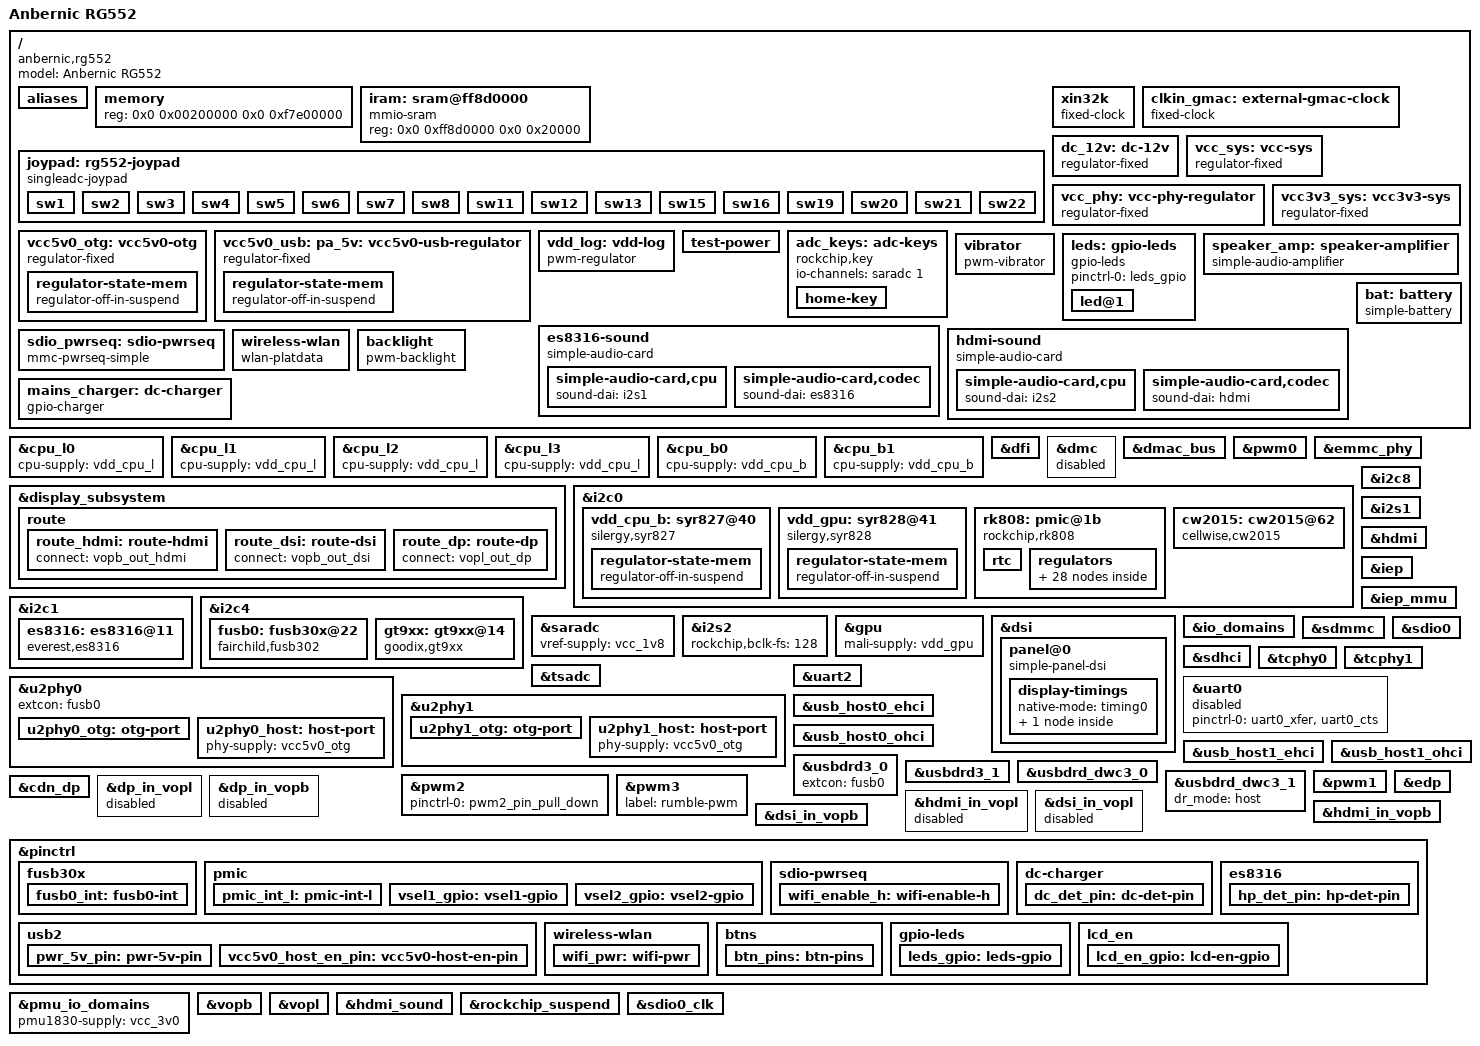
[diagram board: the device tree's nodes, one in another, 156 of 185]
/*
 * Copyright (c) 2017 Fuzhou Rockchip Electronics Co., Ltd
 */

/dts-v1/;
#include <dt-bindings/display/drm_mipi_dsi.h>
#include <dt-bindings/pinctrl/rockchip.h>
#include <dt-bindings/pwm/pwm.h>
#include <dt-bindings/input/input.h>
#include "rk3399.dtsi"
#include "rk3399-android.dtsi"
#include "rk3399-opp.dtsi"
//#include "rk3399-op1-opp.dtsi"
#include "rk3399-vop-clk-set.dtsi"

/ {
	model = "Anbernic RG552";
	compatible = "anbernic,rg552", "rockchip,rk3399";

	aliases {
		mmc0 = &sdio0;
		mmc1 = &sdmmc;
		mmc2 = &sdhci;
	};

	memory {
		device_type = "memory";
		reg = <0x0 0x00200000 0x0 0xf7e00000>;
	};

	
	/* first 64k(0xff8c0000~0xff8d0000) for ddr and suspend */
	iram: sram@ff8d0000 {
		compatible = "mmio-sram";
		reg = <0x0 0xff8d0000 0x0 0x20000>; /* 128k */
	};
	
/*
	gpio_keys: volume-keys {
			compatible = "gpio-keys";
			#address-cells = <1>;
			#size-cells = <0>;
			autorepeat;
			button@0 {
				label = "GPIO BTN-VOLUP";
				linux,code = <KEY_VOLUMEUP>;
				gpios = <&gpio3 RK_PB5 GPIO_ACTIVE_LOW>;
			};
			button@1 {
				label = "GPIO BTN-VOLDN";
				linux,code = <KEY_VOLUMEDOWN>;
				gpios = <&gpio3 RK_PB6 GPIO_ACTIVE_LOW>;
			};
	};
*/
	joypad: rg552-joypad {
		compatible = "singleadc-joypad";
                
		joypad-name = "retrogame_joypad";
		joypad-product = <0x1101>;
		joypad-revision = <0x0100>;
		
		status = "okay";

		/* gpio pincontrol setup */
		pinctrl-names = "default";
		pinctrl-0 = <&btn_pins>;

		/* Analog mux define */
		io-channel-names = "amux_adc";
		io-channels = <&saradc 4>;

		/* adc mux channel count */
		amux-count = <4>;
		/* adc mux select(a,b) gpio */
		amux-a-gpios = <&gpio1 RK_PA1 GPIO_ACTIVE_LOW>;
		amux-b-gpios = <&gpio1 RK_PA0 GPIO_ACTIVE_LOW>;
		/* adc mux enable gpio */
		amux-en-gpios = <&gpio1 RK_PA4 GPIO_ACTIVE_LOW>;

		/* adc calculate scale */
		button-adc-scale = <2>;

		/* adc deadzone range  */
		button-adc-deadzone = <64>;

		/*
		  specifies fuzz value that is used to filter noise from
		  the event stream.
		*/
		button-adc-fuzz = <32>;
		button-adc-flat = <32>;

		/*
		  Analog Stick data tuning value(precent)
		  p = positive direction, n = negative direction
		  report value = (real_adc_data * tuning_value) / 100
		*/
		abs_x-p-tuning = <300>;
		abs_x-n-tuning = <300>;

		abs_y-p-tuning = <300>;
		abs_y-n-tuning = <300>;

		abs_rx-p-tuning = <300>;
		abs_rx-n-tuning = <300>;

		abs_ry-p-tuning = <300>;
		abs_ry-n-tuning = <300>;

		/* poll device interval (ms), adc read interval */
		poll-interval = <10>;

		/* required for RG552(invert) */
		invert-absx;
		invert-absy;

		/* gpio button auto repeat set value : default disable */
		/*
			autorepeat;
		*/

                /*
                               *** RG552 switch layout ***
                |-------------------------------------------------------|
                | sw15(b4) sw21(b6)                   sw20(b7) sw16(b5) |
                |-------------------------------------------------------|
                |        sw19(b12)|-------------------| sw22(b13)       |
                |                 |                   |                 |
                |     sw1(b8)     |                   |     sw8(b2)     |
                |sw3(b10) sw4(b11)|    LCD Display    | sw7(b3) sw5(b1) |
                |     sw2(b9)     |                   |     sw6(b0)     |
                |                 |                   |                 |
                |  sw11(b14)      |-------------------|      sw12(b15)  |
                |                       sw13 (b16)                      |
                |-------------------------------------------------------|
                */

		sw1 {
		        gpios = <&gpio3 RK_PA0 GPIO_ACTIVE_LOW>;
		        label = "GPIO DPAD-UP";
		        linux,code = <103>;
		};
		sw2 {
		        gpios = <&gpio3 RK_PA1 GPIO_ACTIVE_LOW>;
		        label = "GPIO DPAD-DOWN";
		        linux,code = <108>;
		};
		sw3 {
                        gpios = <&gpio3 RK_PA3 GPIO_ACTIVE_LOW>;
		        label = "GPIO DPAD-LEFT";
		        linux,code = <105>;
		};
		sw4 {
                        gpios = <&gpio3 RK_PA2 GPIO_ACTIVE_LOW>;
		        label = "GPIO DPAD-RIGHT";
		        linux,code = <106>;
		};
		sw5 {
		        gpios = <&gpio3 RK_PA6 GPIO_ACTIVE_LOW>;
		        label = "GPIO KEY BTN-A";
		        linux,code = <304>;
		};
		sw6 {
		        gpios = <&gpio3 RK_PA7 GPIO_ACTIVE_LOW>;
		        label = "GPIO BTN-B";
		        linux,code = <305>;
		};
		sw7 {
                        gpios = <&gpio3 RK_PA5 GPIO_ACTIVE_LOW>;
                        label = "GPIO BTN-Y";
                        linux,code = <308>;
                };
                sw8 {
		        gpios = <&gpio3 RK_PA4 GPIO_ACTIVE_LOW>;
		        label = "GPIO BTN-X";
		        linux,code = <307>;
		};
                sw11 {
                        gpios = <&gpio3 RK_PB3 GPIO_ACTIVE_LOW>;
                        label = "GPIO F3";
                        linux,code = <317>;
		};
                sw12 {
                        gpios = <&gpio3 RK_PB4 GPIO_ACTIVE_LOW>;
                        label = "GPIO F4";
                        linux,code = <318>;
		};
                sw13 {
		        gpios = <&gpio3 RK_PC0 GPIO_ACTIVE_LOW>;
                        label = "GPIO F5";
                        linux,code = <127>;
		};
                sw15 {
		        gpios = <&gpio3 RK_PD0 GPIO_ACTIVE_LOW>;
                        label = "GPIO TOP-LEFT";
		        linux,code = <310>;
		};
                sw16 {
		        gpios = <&gpio3 RK_PD2 GPIO_ACTIVE_LOW>;
                        label = "GPIO TOP-RIGHT";
		        linux,code = <311>;
		};
                sw19 {
                        gpios = <&gpio3 RK_PB1 GPIO_ACTIVE_LOW>;
                        label = "GPIO F1";
                        linux,code = <314>;
		};
                sw20 {
		        gpios = <&gpio3 RK_PD3 GPIO_ACTIVE_LOW>;
                        label = "GPIO TOP-RIGHT2";
		        linux,code = <313>;
		};
                sw21 {
                        gpios = <&gpio3 RK_PD1 GPIO_ACTIVE_LOW>;
                        label = "GPIO TOP-LEFT2";
                        linux,code = <312>;
		};
                sw22 {
                        gpios = <&gpio3 RK_PB0 GPIO_ACTIVE_LOW>;
                        label = "GPIO F2";
                        linux,code = <315>;
		};
        };

	xin32k: xin32k {
		compatible = "fixed-clock";
		clock-frequency = <32768>;
		clock-output-names = "xin32k";
		#clock-cells = <0>;
	};

	clkin_gmac: external-gmac-clock {
		compatible = "fixed-clock";
		clock-frequency = <125000000>;
		clock-output-names = "clkin_gmac";
		#clock-cells = <0>;
	};

	dc_12v: dc-12v {
		compatible = "regulator-fixed";
		regulator-name = "dc_12v";
		regulator-always-on;
		regulator-boot-on;
		regulator-min-microvolt = <12000000>;
		regulator-max-microvolt = <12000000>;
	};

	vcc_sys: vcc-sys {
		compatible = "regulator-fixed";
		regulator-name = "vcc_sys";
		regulator-min-microvolt = <5000000>;
		regulator-max-microvolt = <5000000>;
		regulator-always-on;
		vin-supply = <&dc_12v>;
	};

	vcc_phy: vcc-phy-regulator {
		compatible = "regulator-fixed";
		regulator-name = "vcc_phy";
		regulator-always-on;
		regulator-boot-on;
	};

	/* Main 3.3 V supply */
	vcc3v3_sys: vcc3v3-sys {
		compatible = "regulator-fixed";
		regulator-name = "vcc3v3_sys";
		regulator-min-microvolt = <3300000>;
		regulator-max-microvolt = <3300000>;
		regulator-always-on;
		vin-supply = <&vcc_sys>;
	};
	

	/* Regulators supplied by vcc5v0_usb */
	/* USB 3 port power supply regulator  */
	vcc5v0_otg: vcc5v0-otg {
		compatible = "regulator-fixed";
		enable-active-high;
		gpio = <&gpio4 RK_PD2 GPIO_ACTIVE_HIGH>;
		pinctrl-names = "default";
		pinctrl-0 = <&vcc5v0_host_en_pin>;
		regulator-name = "vcc5v0_otg";
		regulator-always-on;
		regulator-min-microvolt = <5000000>;
		regulator-max-microvolt = <5000000>;
		vin-supply = <&vcc5v0_usb>;

		regulator-state-mem {
			regulator-off-in-suspend;
		};
	};
	
	/* 5 V USB power supply */
	vcc5v0_usb: pa_5v: vcc5v0-usb-regulator {
		compatible = "regulator-fixed";
		enable-active-high;
		gpio = <&gpio1 RK_PB5 GPIO_ACTIVE_HIGH>;
		pinctrl-names = "default";
		pinctrl-0 = <&pwr_5v_pin>;
		regulator-name = "vcc5v0_usb";
		regulator-always-on;
		regulator-min-microvolt = <5000000>;
		regulator-max-microvolt = <5000000>;
		vin-supply = <&vcc_sys>;

		regulator-state-mem {
			regulator-off-in-suspend;
		};
	};
	
	/* RK3399 logic supply */
	vdd_log: vdd-log {
		compatible = "pwm-regulator";
		pwms = <&pwm2 0 25000 1>;
		pwm-supply = <&vcc_sys>;
		regulator-name = "vdd_log";
		regulator-min-microvolt = <800000>;
		regulator-max-microvolt = <1400000>;
		regulator-always-on;
		regulator-boot-on;

		/* for rockchip boot on */
		rockchip,pwm_id= <2>;
		rockchip,pwm_voltage = <900000>;
	};

	test-power {
		status = "okay";
	};

	adc_keys: adc-keys {
		compatible = "rockchip,key";
		io-channels = <&saradc 1>;
		io-channel-names = "key_adc";

		home-key {
			linux,code = <172>;
					label = "home";
					rockchip,adc_value = <0>;
		};
	};
/*
	fan0: pwm-fan {
		compatible = "pwm-fan";
		status = "okay";
		pwms = <&pwm1 0 40000 1>;
		#cooling-cells = <2>;
		cooling-levels = <0 76 114 153 178 255>;		
		trig_temp_level0 = <50>;
		trig_temp_level1 = <60>;
		trig_temp_level2 = <70>;
	};
*/

	vibrator {
		compatible = "pwm-vibrator";
		pwms = <&pwm3 0 1000000 0>;
		pwm-names = "enable";
		direction-duty-cycle-ns = <500000>;		
	};

	leds: gpio-leds {
			compatible = "gpio-leds";
			pinctrl-names = "default";
			pinctrl-0 =<&leds_gpio>;

			led@1 {
					gpios = <&gpio1 RK_PC4 GPIO_ACTIVE_HIGH>;
					label = "green";
				//	default-state= "on";
				//	retain-state-suspended;
			};
		/*	
			led@2 {
					gpios = <&gpio3 RK_PD5 GPIO_ACTIVE_HIGH>;
					label = "red";
					default-state= "off";
				//	retain-state-suspended;
			};
		*/	
	};
	
	/* Audio components */
	es8316-sound {
		compatible = "simple-audio-card";
		pinctrl-names = "default";
		pinctrl-0 = <&hp_det_pin>;
		simple-audio-card,name = "rockchip,es8316-codec";
		simple-audio-card,format = "i2s";		
		simple-audio-card,mclk-fs = <256>;
		

		simple-audio-card,widgets =
			"Microphone", "Mic Jack",
			"Headphone", "Headphones",
			"Speaker", "Speaker";
		simple-audio-card,routing =
			"MIC1", "Mic Jack",
			"Headphones", "HPOL",
			"Headphones", "HPOR",
			"Speaker Amplifier INL", "HPOL",
			"Speaker Amplifier INR", "HPOR",
			"Speaker", "Speaker Amplifier OUTL",
			"Speaker", "Speaker Amplifier OUTR";

		simple-audio-card,hp-det-gpio = <&gpio0 RK_PB0 GPIO_ACTIVE_HIGH>;
		simple-audio-card,aux-devs = <&speaker_amp>;
		simple-audio-card,pin-switches = "Speaker";
								
		simple-audio-card,cpu {
			sound-dai = <&i2s1>;
		};
		simple-audio-card,codec {
			sound-dai = <&es8316>;
		};
	};	

	speaker_amp: speaker-amplifier {
		compatible = "simple-audio-amplifier";
		enable-gpios = <&gpio1 RK_PC5 GPIO_ACTIVE_HIGH>;
		sound-name-prefix = "Speaker Amplifier";
		VCC-supply = <&pa_5v>;
	};
	
	hdmi-sound {
		compatible = "simple-audio-card";
		simple-audio-card,format = "i2s";
		simple-audio-card,mclk-fs = <256>;
		simple-audio-card,name = "HDMI";
		simple-audio-card,cpu {
			sound-dai = <&i2s2>;
		};
		simple-audio-card,codec {
			sound-dai = <&hdmi>;
		};
	};

	sdio_pwrseq: sdio-pwrseq {
		compatible = "mmc-pwrseq-simple";
		clocks = <&rk808 1>;
		clock-names = "ext_clock";
		pinctrl-names = "default";
		pinctrl-0 = <&wifi_enable_h>;
	};

	wireless-wlan {
		compatible = "wlan-platdata";
		rockchip,grf = <&grf>;
		wifi_chip_type = "rtl8188fu";
		//sdio_vref = <1800>;
		keep_wifi_power_on;
		WIFI,host_wake_irq = <&gpio0 RK_PA3 GPIO_ACTIVE_HIGH>;
		WIFI,poweren_gpio = <&gpio3 RK_PC1 GPIO_ACTIVE_HIGH>;
		status = "okay";
	};
	
	bat: battery {
		compatible = "simple-battery";
		charge-full-design-microamp-hours = <6400000>;
		voltage-max-design-microvolt = <4350000>;
		voltage-min-design-microvolt = <3400000>;
       //         energy-full-design-microwatt-hours = <11400000>;
        //        precharge-current-microamp = <120000>;
         //       charge-term-current-microamp = <150000>;
                constant-charge-current-max-microamp = <1500000>;
                constant-charge-voltage-max-microvolt = <4350000>;
                factory-internal-resistance-micro-ohms = <150000>;
                resistance-temp-table = <20 150>;
		
                ocv-capacity-celsius = <20>;
                ocv-capacity-table-0 =	<4308000 100>,<4217000 95>,
					<4161000 90>,<4110000 85>,
					<4066000 80>,<4007000 75>,
					<3974000 70>,<3937000 65>,
					<3896000 60>,<3853000 55>,
					<3827000 50>,<3807000 45>,
					<3793000 40>,<3780000 35>,
					<3768000 30>,<3756000 25>,
					<3740000 20>,<3716000 15>,
					<3689000 10>,<3675000 5>,
					<3400000 0>;
	};

	mains_charger: dc-charger {
		compatible = "gpio-charger";
		charger-type = "mains";
		gpios = <&gpio4 RK_PD0 GPIO_ACTIVE_LOW>;
		pinctrl-names = "default";
		pinctrl-0 = <&dc_det_pin>;
		monitored-battery = <&bat>;
	};


	backlight: backlight {
		compatible = "pwm-backlight";
		pwms = <&pwm0 0 25000 0>;
		brightness-levels = <
			  0   1   2   3   4   5   6   7
			  8   9  10  11  12  13  14  15
			 16  17  18  19  20  21  22  23
			 24  25  26  27  28  29  30  31
			 32  33  34  35  36  37  38  39
			 40  41  42  43  44  45  46  47
			 48  49  50  51  52  53  54  55
			 56  57  58  59  60  61  62  63
			 64  65  66  67  68  69  70  71
			 72  73  74  75  76  77  78  79
			 80  81  82  83  84  85  86  87
			 88  89  90  91  92  93  94  95
			 96  97  98  99 100 101 102 103
			104 105 106 107 108 109 110 111
			112 113 114 115 116 117 118 119
			120 121 122 123 124 125 126 127
			128 129 130 131 132 133 134 135
			136 137 138 139 140 141 142 143
			144 145 146 147 148 149 150 151
			152 153 154 155 156 157 158 159
			160 161 162 163 164 165 166 167
			168 169 170 171 172 173 174 175
			176 177 178 179 180 181 182 183
			184 185 186 187 188 189 190 191
			192 193 194 195 196 197 198 199
			200 201 202 203 204 205 206 207
			208 209 210 211 212 213 214 215
			216 217 218 219 220 221 222 223
			224 225 226 227 228 229 230 231
			232 233 234 235 236 237 238 239
			240 241 242 243 244 245 246 247
			248 249 250 251 252 253 254 255>;
		default-brightness-level = <200>;
	};	
};


&cpu_l0 {
	cpu-supply = <&vdd_cpu_l>;
};

&cpu_l1 {
	cpu-supply = <&vdd_cpu_l>;
};

&cpu_l2 {
	cpu-supply = <&vdd_cpu_l>;
};

&cpu_l3 {
	cpu-supply = <&vdd_cpu_l>;
};

&cpu_b0 {
	cpu-supply = <&vdd_cpu_b>;
};

&cpu_b1 {
	cpu-supply = <&vdd_cpu_b>;
};

&dfi {
	status = "okay";
};

&dmc {
        status = "disabled";
        center-supply = <&vdd_center>;
        upthreshold = <40>;
        downdifferential = <20>;
        system-status-freq = <
                /*system status         freq(KHz)*/
                SYS_STATUS_NORMAL       933000
                SYS_STATUS_REBOOT       666000
                SYS_STATUS_SUSPEND      200000
                SYS_STATUS_VIDEO_1080P  666000
                SYS_STATUS_VIDEO_4K     856000
                SYS_STATUS_VIDEO_4K_10B 856000
                SYS_STATUS_PERFORMANCE  933000
                SYS_STATUS_BOOST        856000
                SYS_STATUS_DUALVIEW     856000
                SYS_STATUS_ISP          856000
        >;
        vop-bw-dmc-freq = <
        /* min_bw(MB/s) max_bw(MB/s) freq(KHz) */
                0       762      416000
                763     3012     666000
                3013    99999    856000
        >;

        auto-min-freq = <800000>;
        auto-freq-en = <0>;
};

&dmac_bus {
	iram = <&iram>;
	rockchip,force-iram;
};


&display_subsystem {
	status = "okay";

	route {
		route_hdmi: route-hdmi {
			status = "okay";
			connect = <&vopb_out_hdmi>;
		};

		route_dsi: route-dsi {
			status = "okay";
			connect = <&vopb_out_dsi>;
		};

		route_dp: route-dp {
			connect = <&vopl_out_dp>;
		};
	};
};

/* LCD Backlight PWM */
&pwm0 {
	status = "okay";
};

&emmc_phy {
	status = "okay";
};

&i2c0 {
	status = "okay";
	i2c-scl-rising-time-ns = <180>;
	i2c-scl-falling-time-ns = <30>;
	clock-frequency = <400000>;

	vdd_cpu_b: syr827@40 {
		compatible = "silergy,syr827";
		reg = <0x40>;
		regulator-compatible = "fan53555-reg";
		pinctrl-0 = <&vsel1_gpio>;
		vsel-gpios = <&gpio1 RK_PC1 GPIO_ACTIVE_HIGH>;
		regulator-name = "vdd_cpu_b";
		regulator-min-microvolt = <712500>;
		regulator-max-microvolt = <1500000>;
		regulator-ramp-delay = <1000>;
		fcs,suspend-voltage-selector = <1>;
		regulator-always-on;
		regulator-boot-on;
		vin-supply = <&vcc_sys>;
		regulator-state-mem {
			regulator-off-in-suspend;
		};
	};

	vdd_gpu: syr828@41 {
		compatible = "silergy,syr828";
		reg = <0x41>;
		regulator-compatible = "fan53555-reg";
		pinctrl-0 = <&vsel2_gpio>;
		vsel-gpios = <&gpio1 RK_PB6 GPIO_ACTIVE_HIGH>;
		regulator-name = "vdd_gpu";
		regulator-min-microvolt = <712500>;
		regulator-max-microvolt = <1500000>;
		regulator-enable-ramp-delay = <300>;
		regulator-ramp-delay = <1000>;
		fcs,suspend-voltage-selector = <1>;
		regulator-always-on;
		regulator-boot-on;
		vin-supply = <&vcc_sys>;
		regulator-initial-mode = <1>; /* 1:force PWM 2:auto */
		regulator-state-mem {
			regulator-off-in-suspend;
		};
	};

	rk808: pmic@1b {
		compatible = "rockchip,rk808";
		reg = <0x1b>;
		interrupt-parent = <&gpio3>;
		interrupts = <10 IRQ_TYPE_LEVEL_LOW>;
		pinctrl-names = "default";
		pinctrl-0 = <&pmic_int_l>;
		rockchip,system-power-controller;
		wakeup-source;
		#clock-cells = <1>;
		clock-output-names = "xin32k", "rk808-clkout2";

		vcc1-supply = <&vcc_sys>;
		vcc2-supply = <&vcc_sys>;
		vcc3-supply = <&vcc_sys>;
		vcc4-supply = <&vcc_sys>;
		vcc6-supply = <&vcc_sys>;
		vcc7-supply = <&vcc_sys>;
		vcc8-supply = <&vcc3v3_sys>;
		vcc9-supply = <&vcc_sys>;
		vcc10-supply = <&vcc_sys>;
		vcc11-supply = <&vcc_sys>;
		vcc12-supply = <&vcc3v3_sys>;
		vddio-supply = <&vcc_3v0>;

		rtc {
			status = "okay";
		};

		regulators {
			vdd_center: DCDC_REG1 {
				regulator-name = "vdd_center";
				regulator-min-microvolt = <750000>;
				regulator-max-microvolt = <900000>;
				regulator-ramp-delay = <6001>;
				regulator-always-on;
				regulator-boot-on;
				regulator-state-mem {
					regulator-off-in-suspend;
				};
			};

			vdd_cpu_l: DCDC_REG2 {
				regulator-name = "vdd_cpu_l";
				regulator-min-microvolt = <750000>;
				regulator-max-microvolt = <1350000>;
				regulator-ramp-delay = <6001>;
				regulator-always-on;
				regulator-boot-on;
				regulator-state-mem {
					regulator-off-in-suspend;
				};
			};

			vcc_ddr: DCDC_REG3 {
				regulator-name = "vcc_ddr";
				regulator-always-on;
				regulator-boot-on;
				regulator-state-mem {
					regulator-on-in-suspend;
				};
			};

			vcc_1v8: DCDC_REG4 {
				regulator-name = "vcc_1v8";
				regulator-min-microvolt = <1800000>;
				regulator-max-microvolt = <1800000>;
				regulator-always-on;
				regulator-boot-on;
				regulator-state-mem {
					regulator-on-in-suspend;
					regulator-suspend-microvolt = <1800000>;
				};
			};
				/*LCD power*/
			vcc1v8_dvp: LDO_REG1 {
				regulator-name = "vcc1v8_dvp";
				regulator-min-microvolt = <1800000>;
				regulator-max-microvolt = <1800000>;
				regulator-always-on;
				regulator-boot-on;
				regulator-state-mem {
 					regulator-off-in-suspend;
				};
			};

			vcc3v0_touch: LDO_REG2 {
				regulator-name = "vcc3v0_touch";
				regulator-min-microvolt = <1800000>;
				regulator-max-microvolt = <3300000>;
				regulator-always-on;
				regulator-boot-on;
				regulator-state-mem {
					regulator-off-in-suspend;
				};
			};

			vcca_1v8: LDO_REG3 {
				regulator-name = "vcca_1v8";
				regulator-min-microvolt = <1800000>;
				regulator-max-microvolt = <1800000>;
				regulator-always-on;
				regulator-boot-on;
				regulator-state-mem {
					regulator-on-in-suspend;
					regulator-suspend-microvolt = <1800000>;
				};
			};

			vcc_sd: LDO_REG4 {
				regulator-name = "vcc_sdio";
				regulator-min-microvolt = <1800000>;
				regulator-max-microvolt = <3300000>;
				regulator-always-on;
				regulator-boot-on;
				regulator-state-mem {
					regulator-on-in-suspend;
				};
			};

			vcca3v0_codec: LDO_REG5 {
				regulator-name = "vcca3v0_codec";
				regulator-min-microvolt = <3000000>;
				regulator-max-microvolt = <3000000>;
				regulator-always-on;
				regulator-boot-on;
				regulator-state-mem {
					regulator-off-in-suspend;
				};
			};

			vcc_1v5: LDO_REG6 {
				regulator-name = "vcc_1v5";
				regulator-min-microvolt = <1500000>;
				regulator-max-microvolt = <1500000>;
				regulator-always-on;
				regulator-boot-on;
				regulator-state-mem {
					regulator-on-in-suspend;
					regulator-suspend-microvolt = <1500000>;
				};
			};

			vcca1v8_codec: LDO_REG7 {
				regulator-name = "vcca1v8_codec";
				regulator-min-microvolt = <1800000>;
				regulator-max-microvolt = <1800000>;
				regulator-always-on;
				regulator-boot-on;
				regulator-state-mem {
					regulator-off-in-suspend;
				};
			};

			vcc_3v0: LDO_REG8 {
				regulator-name = "vcc_3v0";
				regulator-min-microvolt = <3000000>;
				regulator-max-microvolt = <3000000>;
				regulator-always-on;
				regulator-boot-on;
				regulator-state-mem {
					regulator-on-in-suspend;
					regulator-suspend-microvolt = <3000000>;
				};
			};

			vcc3v3_s3: SWITCH_REG1 {
				regulator-name = "vcc3v3_s3";
				regulator-always-on;
				regulator-boot-on;
				regulator-state-mem {
					regulator-off-in-suspend;
				};
			};

			vcc3v3_s0: SWITCH_REG2 {
				regulator-name = "vcc3v3_s0";
				regulator-always-on;
				regulator-boot-on;
				regulator-state-mem {
					regulator-off-in-suspend;
				};
			};
		};
	};


	
	cw2015:	cw2015@62 {
		compatible = "cellwise,cw2015";
		reg = <0x62>;
		cellwise,battery-profile = /bits/ 8 <
				   0x15 0x7E 0x66 0x5B 0x58 0x55 0x51 0x4D
				   0x4A 0x47 0x44 0x47 0x4D 0x46 0x32 0x27
				   0x1F 0x1A 0x15 0x16 0x21 0x30 0x3F 0x4A
				   0x46 0x5C 0x0C 0x29 0x19 0x31 0x59 0x74
				   0x7B 0x7D 0x81 0x82 0x3F 0x1A 0x58 0x22
				   0x06 0x42 0x2B 0x63 0x89 0x93 0x94 0x3C
				   0x57 0x7D 0x93 0xAE 0x80 0xC2 0xD2 0xCB
				   0x2F 0x00 0x64 0xA5 0xB5 0x1F 0xB0 0x11
		>;
		cellwise,monitor-interval-ms = <5000>;
		power-supplies = <&mains_charger>;	
		monitored-battery = <&bat>;
	};
};

&i2c1 {
	status = "okay";
	i2c-scl-rising-time-ns = <168>;
	i2c-scl-falling-time-ns = <4>;

	es8316: es8316@11 {
		#sound-dai-cells = <0>;
		compatible = "everest,es8316";
		reg = <0x11>;
		clocks = <&cru SCLK_I2S_8CH_OUT>;
		clock-names = "mclk";
		pinctrl-names = "default";
		pinctrl-0 = <&i2s_8ch_mclk>;
	//	hp-det-gpio = <&gpio0 RK_PB0 GPIO_ACTIVE_HIGH>;
	//	amp-gpio = <&gpio1 RK_PC5 GPIO_ACTIVE_HIGH>;
	};
};

&i2c4 {
	status = "okay";
	fusb0: fusb30x@22 {
		compatible = "fairchild,fusb302";
		reg = <0x22>;
		fusb302,role = "ROLE_MODE_DRP"; //UFP
		pinctrl-names = "default";
		pinctrl-0 = <&fusb0_int>;
		vbus-5v-gpios = <&gpio1 RK_PA3 GPIO_ACTIVE_HIGH>;
		int-n-gpios = <&gpio1 RK_PA2 GPIO_ACTIVE_LOW>; ////high in stock
		status = "okay";

		};

    gt9xx: gt9xx@14 {
        compatible = "goodix,gt9xx";
        reg = <0x14>;
        touch-gpio = <&gpio3 RK_PD7 IRQ_TYPE_EDGE_RISING>;
        reset-gpio = <&gpio3 RK_PD6 GPIO_ACTIVE_LOW>;
		max-x = <1152>;
		max-y = <1920>;
		tp-size = <927>;
 		tp-supply = <&vcc3v0_touch>;		
		status = "okay";
    };
};

&saradc {
	status = "okay";
	vref-supply = <&vcc_1v8>;	
};

&i2c8 {
	status = "okay";
};

&i2s1 {
	status = "okay";
	rockchip,i2s-broken-burst-len;
	rockchip,playback-channels = <8>;
	rockchip,capture-channels = <8>;
};

&i2s2 {
	rockchip,bclk-fs = <128>;
	status = "okay";
};

&gpu {
	status = "okay";
	mali-supply = <&vdd_gpu>;
};

&hdmi {
	#address-cells = <1>;
	#size-cells = <0>;
	#sound-dai-cells = <0>;
	status = "okay";
	rockchip,phy-table =
		<74250000 0x8009 0x0004 0x0272>,
		<165000000 0x802b 0x0004 0x0209>,
		<297000000 0x8039 0x0005 0x028d>,
		<594000000 0x8039 0x0000 0x019d>,
		<000000000 0x0000 0x0000 0x0000>;
};

&dsi {
	status = "okay";

	panel@0 {
		compatible = "simple-panel-dsi";
		reg = <0>;

		/* pwm0 backlight */
		backlight = <&backlight>;

		enable-gpios = <&gpio4 RK_PD1 GPIO_ACTIVE_HIGH>;
 		a_enable-gpios = <&gpio4 RK_PD3 GPIO_ACTIVE_HIGH>;

		/* Rev 0.2 LCD reset gpio GPIO3.C0 */
		reset-gpios = <&gpio0 RK_PB2 GPIO_ACTIVE_HIGH>;

		pinctrl-names = "default";
		pinctrl-0 = <&lcd_en_gpio>;	

		prepare-delay-ms = <2>;
		reset-delay-ms = <150>;
		init-delay-ms = <20>;
		enable-delay-ms = <120>;
		disable-delay-ms = <50>;
		unprepare-delay-ms = <20>;

		/* LCD size */
		width-mm = <69>;
		height-mm = <116>;

		dsi,flags = <(MIPI_DSI_MODE_VIDEO | MIPI_DSI_MODE_VIDEO_BURST |
			MIPI_DSI_MODE_LPM | MIPI_DSI_MODE_EOT_PACKET)>;
		dsi,format = <MIPI_DSI_FMT_RGB888>;
		dsi,lanes = <4>;

		panel-init-sequence = [
			39 00 04 B9 FF 83 99
			39 00 2B E0 01 13 17 34 38 3E 2C 47 07 0C 0F 12 14 11 13 12 18 0B 17 07 13 02 14 18 32 37 3D 29 43 07 0E 0C 0F 11 10 12 12 18 0C 17 07 13
			39 00 0D B1 00 7C 38 35 99 09 22 22 72 F2 68 58 
			15 00 02 D2 99
			39 00 20 D3 00 00 00 00 00 30 30 00 10 05 00 05 00 00 00 00 00 00 00 00 00 00 01 07 07 03 00 00 00 05 08
			39 00 21 D5 00 00 01 00 03 02 00 00 00 00 19 00 18 00 21 20 00 18 00 00 00 00 00 00 00 00 32 32 31 31 30 30	
			39 00 21 D6 40 40 02 03 00 01 40 40 40 40 18 40 19 40 20 21 40 18 40 40 40 40 40 40 40 40 32 32 31 31 30 30
			39 00 31 D8 28 2A 00 2A 28 02 C0 2A 00 00 00 00 00 00 00 00 00 00 00 00 00 00 00 00 00 00 00 00 00 00 00 00 00 00 00 00 00 00 00 00 28 02 00 2A 28 02 C0 2A
			39 00 0B B2 00 80 10 7F 05 01 23 4D 21 01
			39 00 29 B4 00 3F 00 41 00 3D 00 00 00 00 00 01 00 0F 01 02 05 40 00 00 3A 00 41 00 3D 00 00 00 00 00 01 00 0F 01 02 05 00 00 00 3A
			39 00 05 BA 03 82 A0 E5
			05 78 01 11
			05 78 01 29
		];


		/* 28: DisplayOff */
		/* 10: SleepIn */
		panel-exit-sequence = [
			05 00 01 28
			05 00 01 10
		];

		display-timings {
			native-mode = <&timing0>;

			timing0: timing0 {
				clock-frequency = <150000000>;
				hactive = <1152>;
				vactive = <1920>;
				hfront-porch = <64>;
				hsync-len = <4>;
				hback-porch = <30>; //32
				vfront-porch = <56>;
				vsync-len = <3>;
				vback-porch = <21>; //6
				hsync-active = <0>;
				vsync-active = <0>;
				de-active = <0>;
				pixelclk-active = <0>;
			};
		};		
	};
};

&iep {
	status = "okay";
};

&iep_mmu {
	status = "okay";
};

&io_domains {
	status = "okay";
	/*
	 * If the uboot use rkdevelop branch, the io-domain is not set
	 * during uboot phase, it will cause the io voltage is not suit for
	 * the hardware,maybe will damage the io of rk3399, so we add
	 * uboot-set value to make sure the value is same with the kernel,
	 * ofcause you must make sure firstly the value here is suit for your
	 * hardware. The available value is defined in
	 * include/dt-bindings/soc/rockchip-io-domain.h, they are
	 * also list here for more convenient configuration:
	 * bt656-supply: RK3399_BT656_VDD_1V8 or RK3399_BT656_VDD_3V3
	 * audio-supply: RK3399_AUDIO_VDD_1V8 or RK3399_AUDIO_VDD_3V3
	 * gpio1830-supply: RK3399_GPIO1833_VDD_1V8 or RK3399_GPIO1833_VDD_3V3
	 * sdmmc-supply: don't need to configure because the voltage
	 *                       is set in source code during runtime.
	 * NOTE:
	 * 1. The value in uboot-set must be enclosed in "()", otherwise will
	 *     cause compile error.
	 * 2. The uboot-set configuration must be cooperated with submit
	 *     in u-boot.
	 *
	 * Possible supplies for rk3399:
	 * - bt656-supply:  The supply connected to APIO2_VDD.
	 * - audio-supply:  The supply connected to APIO5_VDD.
	 * - sdmmc-supply:  The supply connected to SDMMC0_VDD.
	 * - gpio1830       The supply connected to APIO4_VDD.
	 * 
	 * Possible supplies for rk3399 pmu-domains:
	 * - pmu1830-supply:The supply connected to PMUIO2_VDD.
	 * 
	 */
//	uboot-set = <(RK3399_BT656_VDD_1V8 | RK3399_AUDIO_VDD_1V8 |
//			RK3399_GPIO1833_VDD_3V3)>;
//	bt656-supply = <&vcc1v8_dvp>; /* bt656_gpio2ab_ms */
	audio-supply = <&vcca3v0_codec>; /* audio_gpio3d4a_ms */
	sdmmc-supply = <&vcc_sd>; /* sdmmc_gpio4b_ms */
	gpio1830-supply = <&vcc_3v0>; /* gpio1833_gpio4cd_ms */
};

/*TF1/INT mmcblk1*/
&sdmmc {
	clock-frequency = <150000000>;
	clock-freq-min-max = <100000 150000000>;
	supports-sd;
	bus-width = <4>;
	cap-mmc-highspeed;
	cap-sd-highspeed;
	disable-wp;
	num-slots = <1>;
	sd-uhs-sdr104;
	vqmmc-supply = <&vcc_sd>;
	pinctrl-names = "default";
	pinctrl-0 = <&sdmmc_clk &sdmmc_cmd &sdmmc_cd &sdmmc_bus4>;
	card-detect-delay = <800>;
	status = "okay";
};

/*TF2/EXT mmcblk0*/
&sdio0 {
	clock-frequency = <50000000>;
	max-frequency = <50000000>;
//	supports-sdio;
	supports-sd;
	bus-width = <4>;
	disable-wp;
	cap-sd-highspeed;
	cap-sdio-irq;
	keep-power-in-suspend;
//	mmc-pwrseq = <&sdio_pwrseq>;
	card-detect-delay = <800>;
	cd-gpios = <&gpio2 RK_PC1 GPIO_ACTIVE_LOW>; /*[> CD GPIO <]*/
	num-slots = <1>;
	pinctrl-names = "default";
	pinctrl-0 = <&sdio0_clk &sdio0_cmd &sdio0_cd &sdio0_bus4>;
	sd-uhs-sdr104;
	vqmmc-supply = <&vcc3v0_touch>;
	status = "okay";
};


/*EMMC mmcblk2*/
&sdhci {
	bus-width = <8>;
	mmc-hs400-1_8v;	
	mmc-hs400-enhanced-strobe;
	mmc-hs200-1_8v;
	supports-emmc;
	non-removable;
	keep-power-in-suspend;
	status = "okay";
};


&tcphy0 {
//	rockchip,force_usb2 = <1>;
//	extcon = <&fusb0>;   //breaks usb if enabled
	status = "okay";
};

&tcphy1 {
	status = "okay";
};

&tsadc {
	/* tshut mode 0:CRU 1:GPIO */
	rockchip,hw-tshut-mode = <1>;
	/* tshut polarity 0:LOW 1:HIGH */
	rockchip,hw-tshut-polarity = <1>;
	rockchip,hw-tshut-temp = <110000>;
	status = "okay";
};

&u2phy0 {
	status = "okay";
	extcon = <&fusb0>;

	u2phy0_otg: otg-port {
		status = "okay";
	};

	u2phy0_host: host-port {
		phy-supply = <&vcc5v0_otg>;
		status = "okay";
	};
};

&u2phy1 {
	status = "okay";
	
	u2phy1_otg: otg-port {
		status = "okay";
	};

	u2phy1_host: host-port {
		phy-supply = <&vcc5v0_otg>;
		status = "okay";
	};
};

&uart0 {
	pinctrl-names = "default";
	pinctrl-0 = <&uart0_xfer &uart0_cts>;
	status = "disabled";
};

&uart2 {
	status = "okay";
};

&usb_host0_ehci {
	status = "okay";
};

&usb_host0_ohci {
	status = "okay";
};

&usb_host1_ehci {
	status = "okay";
};

&usb_host1_ohci {
	status = "okay";
};

&usbdrd3_0 {
	extcon = <&fusb0>;  //////disabled in stock
	status = "okay";
};

&usbdrd3_1 {
	status = "okay";
};
/*Left usb port Host works*/
&usbdrd_dwc3_0 {
//	maximum-speed = "high-speed";
	dr_mode = "otg";    ////otg in stock  //peripheral
	status = "okay";
	extcon = <&fusb0>;    /////test enabled
};

/*Host for internal wifi*/
&usbdrd_dwc3_1 {
	dr_mode = "host";
	status = "okay";
};

&pwm1 {
	status = "okay";
};

&pwm2 {
	status = "okay";
	pinctrl-0 = <&pwm2_pin_pull_down>;
};

&pwm3 {
	status = "okay";
	label = "rumble-pwm";
};


&cdn_dp {
	status = "okay";
	extcon = <&fusb0>;
	phys = <&tcphy0_dp>;
};


&dsi {
    status = "okay";
};

&dp_in_vopl {
	status = "disabled";
};

&dp_in_vopb {
	status = "disabled";
};

&edp {
	/delete-property/pinctrl-names;
	/delete-property/pinctrl-0;
};

&hdmi_in_vopl {
	status = "disabled";
};

&hdmi_in_vopb {
	status = "okay";
};

&dsi_in_vopl {
	status = "disabled";
};

&dsi_in_vopb {
	status = "okay";
};

&pinctrl {
	fusb30x {
		fusb0_int: fusb0-int {
			rockchip,pins =
				<1 RK_PA2 RK_FUNC_GPIO &pcfg_pull_up>;
		};		
	};

	pmic {
		pmic_int_l: pmic-int-l {
			rockchip,pins =
				<3 RK_PB2 RK_FUNC_GPIO &pcfg_pull_up>;
		};

		vsel1_gpio: vsel1-gpio {
			rockchip,pins =
				<1 RK_PC1 RK_FUNC_GPIO &pcfg_pull_down>;
		};

		vsel2_gpio: vsel2-gpio {
			rockchip,pins =
				<1 RK_PB6 RK_FUNC_GPIO &pcfg_pull_down>;
		};
	};

	sdio-pwrseq {
		wifi_enable_h: wifi-enable-h {
			rockchip,pins =
				<3 RK_PC1 RK_FUNC_GPIO &pcfg_pull_none>;
		};
	};

	usb2 {
		pwr_5v_pin: pwr-5v-pin {
			rockchip,pins = <1 RK_PB5 RK_FUNC_GPIO &pcfg_pull_none>;
		};

		vcc5v0_host_en_pin: vcc5v0-host-en-pin {
			rockchip,pins = <4 RK_PD2 RK_FUNC_GPIO &pcfg_pull_none>;
		};
	};

	dc-charger {
		dc_det_pin: dc-det-pin {
			rockchip,pins = <4 RK_PD0 RK_FUNC_GPIO &pcfg_pull_up>;
		};
	};

	es8316 {
		hp_det_pin: hp-det-pin {
			rockchip,pins = <0 RK_PB0 RK_FUNC_GPIO &pcfg_pull_up>;
		};		
	};		

	wireless-wlan {
		wifi_pwr: wifi-pwr {
			rockchip,pins = <3 RK_PC1 RK_FUNC_GPIO &pcfg_pull_none>;
		};
	};

};

&pmu_io_domains {
	status = "okay";
	/*
	 * If the uboot use rkdevelop branch, the pmu_io_domain is not set
	 * during uboot phase, it will cause the io voltage is not suit for
	 * the hardware,maybe will damage the io of rk3399, so we add
	 * uboot-set value to make sure the value is same with the kernel,
	 * ofcause you must make sure firstly the value here is suit for your
	 * hardware. The available value is defined in
	 * include/dt-bindings/soc/rockchip-io-domain.h, they are
	 * also list here for more convenient configuration:
	 * pmu1830-supply: RK3399_PMU1830_VDD_1V8 or RK3399_PMU1830_VDD_3V0
	 */
//	uboot-set = <RK3399_PMU1830_VDD_3V0>;
	pmu1830-supply = <&vcc_3v0>;
};

&vopb {
	status = "okay";
	assigned-clocks = <&cru DCLK_VOP0_DIV>;
	assigned-clock-parents = <&cru PLL_VPLL>;
};

&vopl {
	status = "okay";
	assigned-clocks = <&cru DCLK_VOP1_DIV>;
	assigned-clock-parents = <&cru PLL_CPLL>;
};

&hdmi_sound {
	status = "okay";
};

&rockchip_suspend {
	status = "okay";
	rockchip,sleep-debug-en = <0>;
	rockchip,sleep-mode-config = <
		(0
		| RKPM_SLP_ARMPD
		| RKPM_SLP_PERILPPD
		| RKPM_SLP_DDR_RET
		| RKPM_SLP_PLLPD
		| RKPM_SLP_CENTER_PD
		| RKPM_SLP_AP_PWROFF
		)
	>;
	rockchip,wakeup-config = <
		(0
		| RKPM_GPIO_WKUP_EN
		)
	>;
	rockchip,pwm-regulator-config = <
		(0
		| PWM2_REGULATOR_EN
		)
	>;
	rockchip,power-ctrl =
		<&gpio1 RK_PC1 GPIO_ACTIVE_HIGH>,
		<&gpio1 RK_PB6 GPIO_ACTIVE_HIGH>;
};

&sdio0_clk {
	rockchip,pins =
		<2 25 RK_FUNC_1 &pcfg_pull_none>,
		<2 17 RK_FUNC_GPIO &pcfg_pull_up>;
};

&pinctrl {
	btns {
		btn_pins: btn-pins {
			rockchip,pins = 
					<3 RK_PA0 RK_FUNC_GPIO &pcfg_pull_up>,
					<3 RK_PA1 RK_FUNC_GPIO &pcfg_pull_up>,
					<3 RK_PA2 RK_FUNC_GPIO &pcfg_pull_up>,
					<3 RK_PA3 RK_FUNC_GPIO &pcfg_pull_up>,
					<3 RK_PA6 RK_FUNC_GPIO &pcfg_pull_up>,
					<3 RK_PA7 RK_FUNC_GPIO &pcfg_pull_up>,
					<3 RK_PA4 RK_FUNC_GPIO &pcfg_pull_up>,
					<3 RK_PA5 RK_FUNC_GPIO &pcfg_pull_up>,
					<3 RK_PD0 RK_FUNC_GPIO &pcfg_pull_up>,
					<3 RK_PD1 RK_FUNC_GPIO &pcfg_pull_up>,
					<3 RK_PD2 RK_FUNC_GPIO &pcfg_pull_up>,
					<3 RK_PD3 RK_FUNC_GPIO &pcfg_pull_up>,
					<3 RK_PB3 RK_FUNC_GPIO &pcfg_pull_up>,
					<3 RK_PB4 RK_FUNC_GPIO &pcfg_pull_up>,
					<3 RK_PB0 RK_FUNC_GPIO &pcfg_pull_up>,
					<3 RK_PB1 RK_FUNC_GPIO &pcfg_pull_up>,
					<3 RK_PB5 RK_FUNC_GPIO &pcfg_pull_up>,
					<3 RK_PB6 RK_FUNC_GPIO &pcfg_pull_up>,
					<3 RK_PC0 RK_FUNC_GPIO &pcfg_pull_up>;
		};
	};
	
    gpio-leds {
			leds_gpio: leds-gpio {
					rockchip,pins =
							<1 RK_PC4 RK_FUNC_GPIO &pcfg_pull_up>,
							<3 RK_PD5 RK_FUNC_GPIO &pcfg_pull_none>;
			};
	};	
	lcd_en {
		lcd_en_gpio: lcd-en-gpio {
			rockchip,pins =
				<4 RK_PD1 RK_FUNC_GPIO &pcfg_pull_up>,
				<4 RK_PD3 RK_FUNC_GPIO &pcfg_pull_up>;
		};
	};		
};
